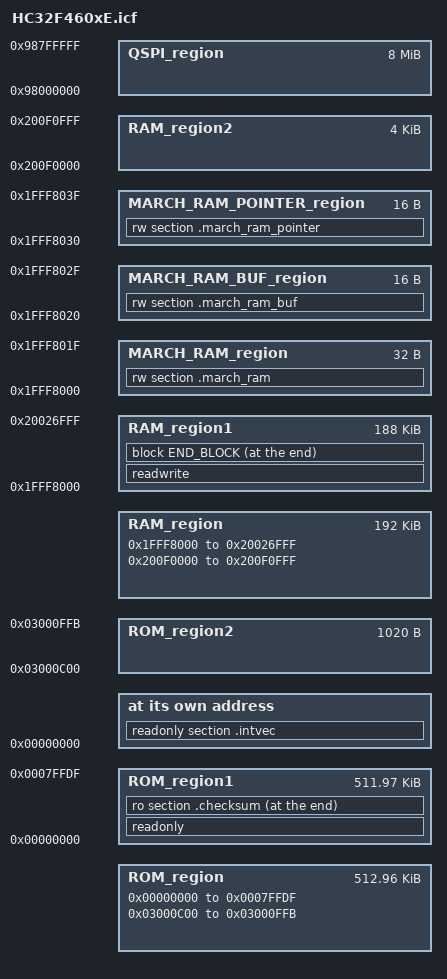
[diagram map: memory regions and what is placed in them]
/*###ICF### Section handled by ICF editor, don't touch! ****/
/*-Editor annotation file-*/
/* IcfEditorFile="$TOOLKIT_DIR$\config\ide\IcfEditor\cortex_v1_4.xml" */
/*-Specials-*/
define symbol __ICFEDIT_intvec_start__ = 0x00000000;
/*-Memory Regions-*/
define symbol __ICFEDIT_region_IROM1_start__             = 0x00000000;
define symbol __ICFEDIT_region_IROM1_end__               = 0x0007FFDF;
define symbol __ICFEDIT_region_IROM2_start__             = 0x03000C00;
define symbol __ICFEDIT_region_IROM2_end__               = 0x03000FFB;
define symbol __ICFEDIT_region_EROM1_start__             = 0x98000000;
define symbol __ICFEDIT_region_EROM1_end__               = 0x987FFFFF;
define symbol __ICFEDIT_region_EROM2_start__             = 0x0;
define symbol __ICFEDIT_region_EROM2_end__               = 0x0;
define symbol __ICFEDIT_region_EROM3_start__             = 0x0;
define symbol __ICFEDIT_region_EROM3_end__               = 0x0;
define symbol __ICFEDIT_region_IRAM1_start__             = 0x1FFF8000;
define symbol __ICFEDIT_region_IRAM1_end__               = 0x20026FFF;
define symbol __ICFEDIT_region_IRAM2_start__             = 0x200F0000;
define symbol __ICFEDIT_region_IRAM2_end__               = 0x200F0FFF;
define symbol __ICFEDIT_region_ERAM1_start__             = 0x0;
define symbol __ICFEDIT_region_ERAM1_end__               = 0x0;
define symbol __ICFEDIT_region_ERAM2_start__             = 0x0;
define symbol __ICFEDIT_region_ERAM2_end__               = 0x0;
define symbol __ICFEDIT_region_ERAM3_start__             = 0x0;
define symbol __ICFEDIT_region_ERAM3_end__               = 0x0;
define symbol __ICFEDIT_region_MARCH_RAM_start__         = 0x1FFF8000;
define symbol __ICFEDIT_region_MARCH_RAM_end__           = 0x1FFF801F;
define symbol __ICFEDIT_region_MARCH_RAM_BUF_start__     = 0x1FFF8020;
define symbol __ICFEDIT_region_MARCH_RAM_BUF_end__       = 0x1FFF802F;
define symbol __ICFEDIT_region_MARCH_RAM_POINTER_start__ = 0x1FFF8030;
define symbol __ICFEDIT_region_MARCH_RAM_POINTER_end__   = 0x1FFF803F;

/*-Sizes-*/
define symbol __ICFEDIT_size_cstack__         = 0x2000;
define symbol __ICFEDIT_size_proc_stack__     = 0x0;
define symbol __ICFEDIT_size_heap__           = 0x2000;
define symbol __ICFEDIT_size_stack_boundary__ = 0x10;
/**** End of ICF editor section. ###ICF###*/

export symbol __ICFEDIT_region_IROM1_start__;
export symbol __ICFEDIT_region_IROM1_end__;
export symbol __ICFEDIT_region_IRAM1_start__;
export symbol __ICFEDIT_region_IRAM1_end__;
export symbol __ICFEDIT_region_MARCH_RAM_start__;
export symbol __ICFEDIT_region_MARCH_RAM_end__;
export symbol __ICFEDIT_region_IRAM2_start__;
export symbol __ICFEDIT_region_IRAM2_end__;

define memory mem with size = 4G;
define region ROM_region       =   mem:[from __ICFEDIT_region_IROM1_start__   to __ICFEDIT_region_IROM1_end__]
                                 | mem:[from __ICFEDIT_region_IROM2_start__   to __ICFEDIT_region_IROM2_end__];
define region QSPI_region      =   mem:[from __ICFEDIT_region_EROM1_start__   to __ICFEDIT_region_EROM1_end__];
define region RAM_region       =   mem:[from __ICFEDIT_region_IRAM1_start__   to __ICFEDIT_region_IRAM1_end__]
                                 | mem:[from __ICFEDIT_region_IRAM2_start__   to __ICFEDIT_region_IRAM2_end__];
define region ROM_region1   = mem:[from __ICFEDIT_region_IROM1_start__   to __ICFEDIT_region_IROM1_end__];
define region ROM_region2   = mem:[from __ICFEDIT_region_IROM2_start__   to __ICFEDIT_region_IROM2_end__];
define region RAM_region1   = mem:[from __ICFEDIT_region_IRAM1_start__   to __ICFEDIT_region_IRAM1_end__];
define region RAM_region2   = mem:[from __ICFEDIT_region_IRAM2_start__   to __ICFEDIT_region_IRAM2_end__];

define region MARCH_RAM_region         = mem:[from __ICFEDIT_region_MARCH_RAM_start__   to __ICFEDIT_region_MARCH_RAM_end__];
define region MARCH_RAM_BUF_region     = mem:[from __ICFEDIT_region_MARCH_RAM_BUF_start__   to __ICFEDIT_region_MARCH_RAM_BUF_end__];
define region MARCH_RAM_POINTER_region = mem:[from __ICFEDIT_region_MARCH_RAM_POINTER_start__   to __ICFEDIT_region_MARCH_RAM_POINTER_end__];

define block CSTACK    with alignment = 8, size = __ICFEDIT_size_cstack__   { };
define block HEAP      with alignment = 8, size = __ICFEDIT_size_heap__     { };
define block STACK_BOUNDARY  with alignment = 8, size = __ICFEDIT_size_stack_boundary__  { section .stack_boundary };
define block END_BLOCK       with fixed order { block STACK_BOUNDARY, block CSTACK, block HEAP };

initialize by copy { readwrite };
do not initialize  { section .noinit, section STACK_BOUNDARY };

place at address mem:__ICFEDIT_intvec_start__ { readonly section .intvec };

place in ROM_region1                { readonly };
place at end of ROM_region1         { ro section .checksum };

place in MARCH_RAM_region           { rw section .march_ram};
place in MARCH_RAM_BUF_region       { rw section .march_ram_buf};
place in MARCH_RAM_POINTER_region   { rw section .march_ram_pointer};
place in RAM_region1                { readwrite};
place at end of RAM_region1         { block END_BLOCK };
